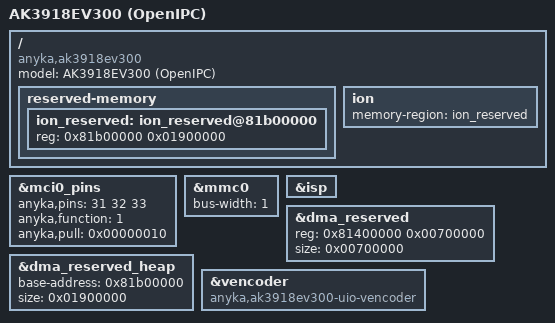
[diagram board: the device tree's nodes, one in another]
/*
 * AK3918EV300 (and its AK3916/AK3919 packages) as OpenIPC boots it: the
 * EV330 board of ak3918ev330-demb, with the bootargs, memory, ISP pool,
 * MIPI/DVP and RMII pads and UART0 it sets up, on the AnyCloud39EV300
 * silicon that came before the EV330.
 */

#include "ak3918ev330-demb.dts"
#include "anycloud_ak3918ev300.dtsi"

/ {
	model = "AK3918EV300 (OpenIPC)";
	compatible = "anyka,ak3918ev300";
};

/*
 * Every board in the Cloud39EV300 SDK runs the SD slot 1-bit on pads 31-33
 * (mci1_plat_data .bus_width = MCI_BUS_WIDTH_1), and so does Anyka's own
 * U-Boot for it. The EVB's D1-D3 on pads 34, 80 and 81 are not SD data on
 * EV300 boards: 4-bit reads fail with -EILSEQ on every block
 * (OpenIPC/firmware#2639).
 */
&mci0_pins {
	anyka,pins = <31 32 33>;
	anyka,function = <1>;
	anyka,pull = <0x00000010>;
};

&mmc0 {
	bus-width = <1>;
};

/*
 * The MIPI pads need no mux on EV300. The EV330 groups this board inherits
 * (pins 70-75, functions 3 and 2) write 0x01F80000 into SHAREPIN_CON1
 * (sysctrl 0x78), and with those bits set the ISP never sees a frame. The
 * stock EV300 kernel's MIPI pin group writes nothing, and 0x78 reads 0 while
 * it streams (OpenIPC/firmware#2639, TECKIN TC100 with a JX-F23). So EV300
 * keeps the DVP pads as they are and only the D-PHY is switched to MIPI.
 */
&isp {
	pinctrl-names = "default";
	/delete-property/ pinctrl-1;
	/delete-property/ pinctrl-2;
};

/*
 * The H.264/H.265 encoder is an Allegro core driven by the SDK's userspace
 * library (libakv_encode), which needs physically contiguous memory for its
 * reference frames and stream buffers, and wants the capture buffers there
 * too so it can read them in place. The EV330 board gives the whole 24 MB
 * pool to the ISP host; here the ISP keeps 7 MB for what it allocates itself
 * (the 1080p 3D-NR reference frame is 6.2 MB) and an ION carve-out after it
 * holds the rest: three 1080p capture buffers with their sub channel (10.4 MB)
 * and the encoder (7.3 MB for a 1080p H.264 or H.265 channel, 0.95 MB for
 * 640x360, 0.83 MB for 1080p JPEG, as libakv_encode V2.2.21 asks for them).
 * 32 MB in all, leaving Linux 32 MB; the SDK's own EV300 kernels reserve 34.
 */
/ {
	reserved-memory {
		ion_reserved: ion_reserved@81b00000 {
			reg = <0x81b00000 0x01900000>;
		};
	};

	ion {
		memory-region = <&ion_reserved>;
		status = "okay";
	};
};

&dma_reserved {
	reg = <0x81400000 0x00700000>;
	size = <0x00700000>;
};

&dma_reserved_heap {
	base-address = <0x81b00000>;
	size = <0x01900000>;
};

&vencoder {
	compatible = "anyka,ak3918ev300-uio-vencoder";
	status = "okay";
};
